AUTOSAR XML (schema 4-2-2)
package /STELLANTIS/EPT/ASWCs
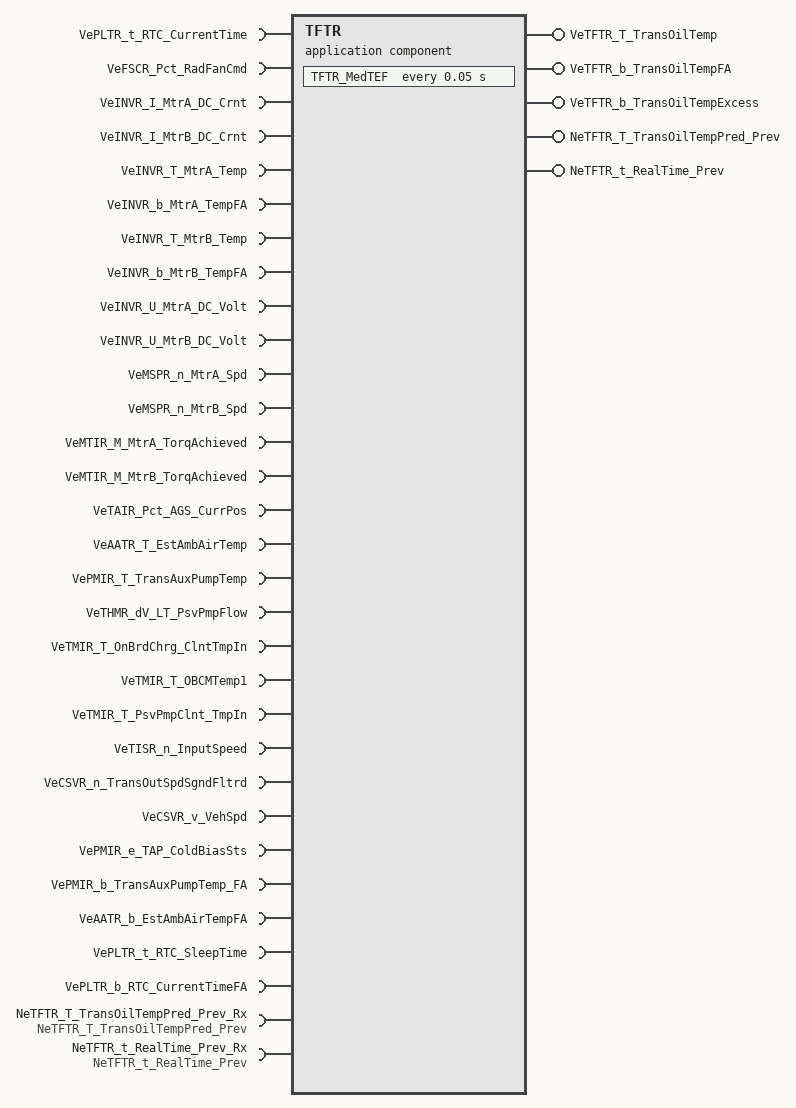
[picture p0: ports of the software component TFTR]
  application sw component type TFTR
    29 x require port:
      VePLTR_t_RTC_CurrentTime: nonqueued-receiver-com-spec{data-element=Value, init-value=0}, required-interface=VePLTR_t_RTC_CurrentTime
      VeFSCR_Pct_RadFanCmd: nonqueued-receiver-com-spec{data-element=Value, init-value=0}, required-interface=VeFSCR_Pct_RadFanCmd
      VeINVR_I_MtrA_DC_Crnt: nonqueued-receiver-com-spec{data-element=Value, init-value=0}, required-interface=VeINVR_I_MtrA_DC_Crnt
      VeINVR_I_MtrB_DC_Crnt: nonqueued-receiver-com-spec{data-element=Value, init-value=0}, required-interface=VeINVR_I_MtrB_DC_Crnt
      VeINVR_T_MtrA_Temp: nonqueued-receiver-com-spec{data-element=Value, init-value=0}, required-interface=VeINVR_T_MtrA_Temp
      VeINVR_b_MtrA_TempFA: nonqueued-receiver-com-spec{data-element=Value, init-value=0}, required-interface=VeINVR_b_MtrA_TempFA
      VeINVR_T_MtrB_Temp: nonqueued-receiver-com-spec{data-element=Value, init-value=0}, required-interface=VeINVR_T_MtrB_Temp
      VeINVR_b_MtrB_TempFA: nonqueued-receiver-com-spec{data-element=Value, init-value=0}, required-interface=VeINVR_b_MtrB_TempFA
      VeINVR_U_MtrA_DC_Volt: nonqueued-receiver-com-spec{data-element=Value, init-value=0}, required-interface=VeINVR_U_MtrA_DC_Volt
      VeINVR_U_MtrB_DC_Volt: nonqueued-receiver-com-spec{data-element=Value, init-value=0}, required-interface=VeINVR_U_MtrB_DC_Volt
      VeMSPR_n_MtrA_Spd: nonqueued-receiver-com-spec{data-element=Value, init-value=0}, required-interface=VeMSPR_n_MtrA_Spd
      VeMSPR_n_MtrB_Spd: nonqueued-receiver-com-spec{data-element=Value, init-value=0}, required-interface=VeMSPR_n_MtrB_Spd
      VeMTIR_M_MtrA_TorqAchieved: nonqueued-receiver-com-spec{data-element=Value, init-value=0}, required-interface=VeMTIR_M_MtrA_TorqAchieved
      VeMTIR_M_MtrB_TorqAchieved: nonqueued-receiver-com-spec{data-element=Value, init-value=0}, required-interface=VeMTIR_M_MtrB_TorqAchieved
      VeTAIR_Pct_AGS_CurrPos: nonqueued-receiver-com-spec{data-element=Value, init-value=0}, required-interface=VeTAIR_Pct_AGS_CurrPos
      VeAATR_T_EstAmbAirTemp: nonqueued-receiver-com-spec{data-element=Value, init-value=0}, required-interface=VeAATR_T_EstAmbAirTemp
      VePMIR_T_TransAuxPumpTemp: nonqueued-receiver-com-spec{data-element=Value, init-value=0}, required-interface=VePMIR_T_TransAuxPumpTemp
      VeTHMR_dV_LT_PsvPmpFlow: nonqueued-receiver-com-spec{data-element=Value, init-value=0}, required-interface=VeTHMR_dV_LT_PsvPmpFlow
      VeTMIR_T_OnBrdChrg_ClntTmpIn: nonqueued-receiver-com-spec{data-element=Value, init-value=0}, required-interface=VeTMIR_T_OnBrdChrg_ClntTmpIn
      VeTMIR_T_OBCMTemp1: nonqueued-receiver-com-spec{data-element=Value, init-value=0}, required-interface=VeTMIR_T_OBCMTemp1
      VeTMIR_T_PsvPmpClnt_TmpIn: nonqueued-receiver-com-spec{data-element=Value, init-value=0}, required-interface=VeTMIR_T_PsvPmpClnt_TmpIn
      VeTISR_n_InputSpeed: nonqueued-receiver-com-spec{data-element=Value, init-value=0}, required-interface=VeTISR_n_InputSpeed
      VeCSVR_n_TransOutSpdSgndFltrd: nonqueued-receiver-com-spec{data-element=Value, init-value=0}, required-interface=VeCSVR_n_TransOutSpdSgndFltrd
      VeCSVR_v_VehSpd: nonqueued-receiver-com-spec{data-element=Value, init-value=0}, required-interface=VeCSVR_v_VehSpd
      VePMIR_e_TAP_ColdBiasSts: nonqueued-receiver-com-spec{data-element=Value, init-value=CeTAPR_e_TAP_FalseTrueSNA_False}, required-interface=VePMIR_e_TAP_ColdBiasSts
      VePMIR_b_TransAuxPumpTemp_FA: nonqueued-receiver-com-spec{data-element=Value, init-value=0}, required-interface=VePMIR_b_TransAuxPumpTemp_FA
      VeAATR_b_EstAmbAirTempFA: nonqueued-receiver-com-spec{data-element=Value, init-value=0}, required-interface=VeAATR_b_EstAmbAirTempFA
      VePLTR_t_RTC_SleepTime: nonqueued-receiver-com-spec{data-element=Value, init-value=0}, required-interface=VePLTR_t_RTC_SleepTime
      VePLTR_b_RTC_CurrentTimeFA: nonqueued-receiver-com-spec{data-element=Value, init-value=0}, required-interface=VePLTR_b_RTC_CurrentTimeFA
    provide port VeTFTR_T_TransOilTemp: variation-point={short-label=vpVeTFTR_T_TransOilTemp, sw-syscond=1}, nonqueued-sender-com-spec{data-element=Value, init-value=0}, provided-interface=VeTFTR_T_TransOilTemp
    provide port VeTFTR_b_TransOilTempFA: variation-point={short-label=vpVeTFTR_b_TransOilTempFA, sw-syscond=1}, nonqueued-sender-com-spec{data-element=Value, init-value=0}, provided-interface=VeTFTR_b_TransOilTempFA
    provide port VeTFTR_b_TransOilTempExcess: variation-point={short-label=vpVeTFTR_b_TransOilTempExcess, sw-syscond=1}, nonqueued-sender-com-spec{data-element=Value, init-value=0}, provided-interface=VeTFTR_b_TransOilTempExcess
    require port NeTFTR_T_TransOilTempPred_Prev_Rx: nv-require-com-spec{init-value=25, variable=NeTFTR_T_TransOilTempPred_Prev}, required-interface=NeTFTR_T_TransOilTempPred_Prev
    require port NeTFTR_t_RealTime_Prev_Rx: nv-require-com-spec{init-value=0, variable=NeTFTR_t_RealTime_Prev}, required-interface=NeTFTR_t_RealTime_Prev
    provide port NeTFTR_T_TransOilTempPred_Prev: nv-provide-com-spec{ram-block-init-value=25, variable=NeTFTR_T_TransOilTempPred_Prev}, provided-interface=NeTFTR_T_TransOilTempPred_Prev
    provide port NeTFTR_t_RealTime_Prev: nv-provide-com-spec{ram-block-init-value=0, variable=NeTFTR_t_RealTime_Prev}, provided-interface=NeTFTR_t_RealTime_Prev
    behavior IB_TFTR: data-type-mapping=msADTtoIDTMapping, handle-termination-and-restart=NO-SUPPORT
      timing event Event_MedTEF: start-on-event=TFTR_MedTEF, period=0.05
      init event Event_TFTR_ac_Init: start-on-event=TFTR_ac_Init
      init event Event_PwrOn: start-on-event=TFTR_PwrOn
      init event Event_PwrOff: start-on-event=TFTR_PwrOff
      explicit-inter-runnable-variables:
        data TFTR_TransOilTemp_write_IRV: category=VALUE, sw-calibration-access=READ-ONLY, type=Float, init-value=0, variation-point={short-label=vpTFTR_TransOilTemp_write_IRV, sw-syscond=1}
        data TFTR_TransOilTempFA_write_IRV: category=VALUE, sw-calibration-access=READ-ONLY, type=Boolean, init-value=0, variation-point={short-label=vpTFTR_TransOilTempFA_write_IRV, sw-syscond=1}
      4 x runnable:
        TFTR_ac_Init
          data-send-points:
            access OUT_VeTFTR_T_TransOilTemp_Value: accessed-variable=VeTFTR_T_TransOilTemp.Value, variation-point={short-label=vpOUT_VeTFTR_T_TransOilTemp_Value, sw-syscond=1}
            access OUT_VeTFTR_b_TransOilTempFA_Value: accessed-variable=VeTFTR_b_TransOilTempFA.Value, variation-point={short-label=vpOUT_VeTFTR_b_TransOilTempFA_Value, sw-syscond=1}
            access OUT_VeTFTR_b_TransOilTempExcess_Value: accessed-variable=VeTFTR_b_TransOilTempExcess.Value, variation-point={short-label=vpOUT_VeTFTR_b_TransOilTempExcess_Value, sw-syscond=1}
        TFTR_PwrOn
          data-receive-point-by-arguments:
            access IN_NeTFTR_T_TransOilTempPred_Prev_Rx_NeTFTR_T_TransOilTempPred_Prev: accessed-variable=NeTFTR_T_TransOilTempPred_Prev_Rx.NeTFTR_T_TransOilTempPred_Prev
            access IN_NeTFTR_t_RealTime_Prev_Rx_NeTFTR_t_RealTime_Prev: accessed-variable=NeTFTR_t_RealTime_Prev_Rx.NeTFTR_t_RealTime_Prev
          data-send-points:
            access OUT_VeTFTR_T_TransOilTemp_Value: accessed-variable=VeTFTR_T_TransOilTemp.Value, variation-point={short-label=vpOUT_VeTFTR_T_TransOilTemp_Value, sw-syscond=1}
            access OUT_VeTFTR_b_TransOilTempFA_Value: accessed-variable=VeTFTR_b_TransOilTempFA.Value, variation-point={short-label=vpOUT_VeTFTR_b_TransOilTempFA_Value, sw-syscond=1}
            access OUT_VeTFTR_b_TransOilTempExcess_Value: accessed-variable=VeTFTR_b_TransOilTempExcess.Value, variation-point={short-label=vpOUT_VeTFTR_b_TransOilTempExcess_Value, sw-syscond=1}
          written-local-variables:
            access WV_TFTR_TransOilTempFA_write_IRV: accessed-variable=TFTR_TransOilTempFA_write_IRV, variation-point={short-label=vpWV_TFTR_TransOilTempFA_write_IRV, sw-syscond=1}
            access WV_TFTR_TransOilTemp_write_IRV: accessed-variable=TFTR_TransOilTemp_write_IRV, variation-point={short-label=vpWV_TFTR_TransOilTemp_write_IRV, sw-syscond=1}
        TFTR_MedTEF
          data-receive-point-by-arguments:
            29 x access:
              IN_VeAATR_T_EstAmbAirTemp_Value: accessed-variable=VeAATR_T_EstAmbAirTemp.Value
              IN_VeAATR_b_EstAmbAirTempFA_Value: accessed-variable=VeAATR_b_EstAmbAirTempFA.Value
              IN_VeCSVR_n_TransOutSpdSgndFltrd_Value: accessed-variable=VeCSVR_n_TransOutSpdSgndFltrd.Value
              IN_VeCSVR_v_VehSpd_Value: accessed-variable=VeCSVR_v_VehSpd.Value
              IN_VeFSCR_Pct_RadFanCmd_Value: accessed-variable=VeFSCR_Pct_RadFanCmd.Value
              IN_VeINVR_I_MtrA_DC_Crnt_Value: accessed-variable=VeINVR_I_MtrA_DC_Crnt.Value
              IN_VeINVR_I_MtrB_DC_Crnt_Value: accessed-variable=VeINVR_I_MtrB_DC_Crnt.Value
              IN_VeINVR_T_MtrA_Temp_Value: accessed-variable=VeINVR_T_MtrA_Temp.Value
              IN_VeINVR_T_MtrB_Temp_Value: accessed-variable=VeINVR_T_MtrB_Temp.Value
              IN_VeINVR_U_MtrA_DC_Volt_Value: accessed-variable=VeINVR_U_MtrA_DC_Volt.Value
              IN_VeINVR_U_MtrB_DC_Volt_Value: accessed-variable=VeINVR_U_MtrB_DC_Volt.Value
              IN_VeINVR_b_MtrA_TempFA_Value: accessed-variable=VeINVR_b_MtrA_TempFA.Value
              IN_VeINVR_b_MtrB_TempFA_Value: accessed-variable=VeINVR_b_MtrB_TempFA.Value
              IN_VeMSPR_n_MtrA_Spd_Value: accessed-variable=VeMSPR_n_MtrA_Spd.Value
              IN_VeMSPR_n_MtrB_Spd_Value: accessed-variable=VeMSPR_n_MtrB_Spd.Value
              IN_VeMTIR_M_MtrA_TorqAchieved_Value: accessed-variable=VeMTIR_M_MtrA_TorqAchieved.Value
              IN_VeMTIR_M_MtrB_TorqAchieved_Value: accessed-variable=VeMTIR_M_MtrB_TorqAchieved.Value
              IN_VePLTR_b_RTC_CurrentTimeFA_Value: accessed-variable=VePLTR_b_RTC_CurrentTimeFA.Value
              IN_VePLTR_t_RTC_CurrentTime_Value: accessed-variable=VePLTR_t_RTC_CurrentTime.Value
              IN_VePLTR_t_RTC_SleepTime_Value: accessed-variable=VePLTR_t_RTC_SleepTime.Value
              IN_VePMIR_T_TransAuxPumpTemp_Value: accessed-variable=VePMIR_T_TransAuxPumpTemp.Value
              IN_VePMIR_b_TransAuxPumpTemp_FA_Value: accessed-variable=VePMIR_b_TransAuxPumpTemp_FA.Value
              IN_VePMIR_e_TAP_ColdBiasSts_Value: accessed-variable=VePMIR_e_TAP_ColdBiasSts.Value
              IN_VeTAIR_Pct_AGS_CurrPos_Value: accessed-variable=VeTAIR_Pct_AGS_CurrPos.Value
              IN_VeTHMR_dV_LT_PsvPmpFlow_Value: accessed-variable=VeTHMR_dV_LT_PsvPmpFlow.Value
              IN_VeTISR_n_InputSpeed_Value: accessed-variable=VeTISR_n_InputSpeed.Value
              IN_VeTMIR_T_OBCMTemp1_Value: accessed-variable=VeTMIR_T_OBCMTemp1.Value
              IN_VeTMIR_T_OnBrdChrg_ClntTmpIn_Value: accessed-variable=VeTMIR_T_OnBrdChrg_ClntTmpIn.Value
              IN_VeTMIR_T_PsvPmpClnt_TmpIn_Value: accessed-variable=VeTMIR_T_PsvPmpClnt_TmpIn.Value
          data-send-points:
            access OUT_VeTFTR_T_TransOilTemp_Value: accessed-variable=VeTFTR_T_TransOilTemp.Value, variation-point={short-label=vpOUT_VeTFTR_T_TransOilTemp_Value, sw-syscond=1}
            access OUT_VeTFTR_b_TransOilTempFA_Value: accessed-variable=VeTFTR_b_TransOilTempFA.Value, variation-point={short-label=vpOUT_VeTFTR_b_TransOilTempFA_Value, sw-syscond=1}
            access OUT_VeTFTR_b_TransOilTempExcess_Value: accessed-variable=VeTFTR_b_TransOilTempExcess.Value, variation-point={short-label=vpOUT_VeTFTR_b_TransOilTempExcess_Value, sw-syscond=1}
        TFTR_PwrOff
          data-send-points:
            access OUT_NeTFTR_T_TransOilTempPred_Prev_NeTFTR_T_TransOilTempPred_Prev: accessed-variable=NeTFTR_T_TransOilTempPred_Prev.NeTFTR_T_TransOilTempPred_Prev
            access OUT_NeTFTR_t_RealTime_Prev_NeTFTR_t_RealTime_Prev: accessed-variable=NeTFTR_t_RealTime_Prev.NeTFTR_t_RealTime_Prev
      8 x variation point proxy, all with category=CONDITION:
        Variant_TFTR_1: condition-access=0
        Variant_TFTR_2: condition-access=1
        Variant_TFTR_{3..5}: condition-access=0
        Variant_TFTR_6: condition-access=1
        Variant_TFTR_7: condition-access=0
        Variant_TFTR_8: condition-access=0
